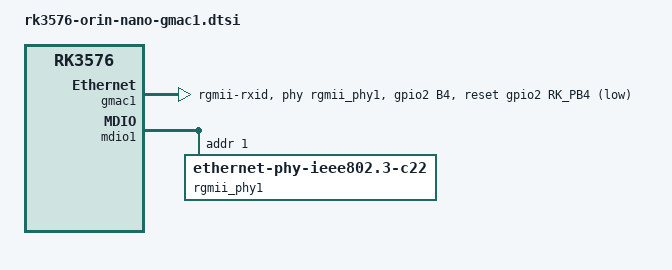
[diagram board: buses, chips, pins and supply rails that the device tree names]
// SPDX-License-Identifier: (GPL-2.0+ OR MIT)
/*
 * Guangzhou Easy EAI Technology Co., Ltd.
 *
 */

&gmac1 {
	/* Use rgmii-rxid mode to disable rx delay inside Soc */
	phy-mode = "rgmii-rxid";
	clock_in_out = "output";
	snps,reset-gpio = <&gpio2 RK_PB4 GPIO_ACTIVE_LOW>;
	snps,reset-active-low;
	/* Reset time is 20ms, 100ms for rtl8211f */
	snps,reset-delays-us = <0 20000 100000>;

	pinctrl-names = "default";
	pinctrl-0 = <&eth1m0_miim
		 &eth1m0_tx_bus2
		 &eth1m0_rx_bus2
		 &eth1m0_rgmii_clk
		 &eth1m0_rgmii_bus
		 &gmac1_rst_pin>;

	tx_delay = <0x20>;
	/* rx_delay = <0x3f>; */

	phy-handle = <&rgmii_phy1>;
	status = "okay";
};

&mdio1 {
	rgmii_phy1: phy@1 {
		compatible = "ethernet-phy-ieee802.3-c22";
		reg = <0x1>;
		/* 关闭CLKOUT信号 */
        	realtek,clkout-disable;
	};
};

&pinctrl {
	gmac1 {
		gmac1_rst_pin: gmac1-rst-pin {
			rockchip,pins = <2 RK_PB4 RK_FUNC_GPIO &pcfg_pull_none>;
		};
	};
};


